# 32-kHz_Sync_Timer register map
Vendor: Texas Instruments
Peripheral module from a debugger description file (folder omap36xx).
Registers are 32-bit, read-only, reset 0x0 unless marked. A register's access mark holds for its fields unless they carry their own. Offsets are as the file gives them; lines under a group give offsets from that group; [hi:lo] are bit positions; {n}, {i} and the like mark numbered series; 'fields as' and 'values as' point back to an identical list; <NAME> marks a mode.

## 32-kHz_Sync_Timer
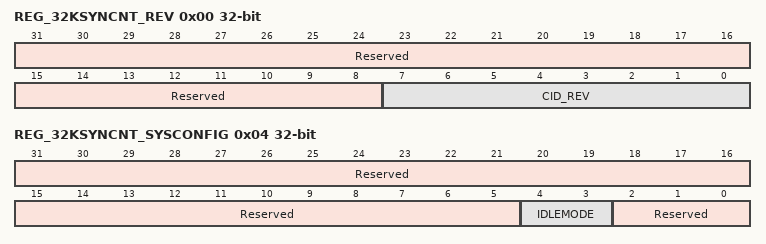
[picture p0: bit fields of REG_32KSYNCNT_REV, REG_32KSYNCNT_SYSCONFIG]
0x00 REG_32KSYNCNT_REV (reset mask 0xFFFFFF00) — This register contains the sync counter IP revision code.
  [31:8] Reserved — Reads return 0.
  [7:0] CID_REV — Counter revision number[7:4] = Major revision . [3:0] = Minor revision . (Examples: 0x10 for 1.0, 0x21 for 2.1) .
0x04 REG_32KSYNCNT_SYSCONFIG access per field — This register is used for IDLE modes only.
  [31:5] Reserved ro — Reads return 0.
  [4:3] IDLEMODE rw — Power management REQ/ACK control
  [2:0] Reserved ro — Reads return 0.
0x10 REG_32KSYNCNT_CR reset 0x3 — This register contains the 32-kHz sync counter value.
  [31:0] COUNTER_VALUE — Counter register value
